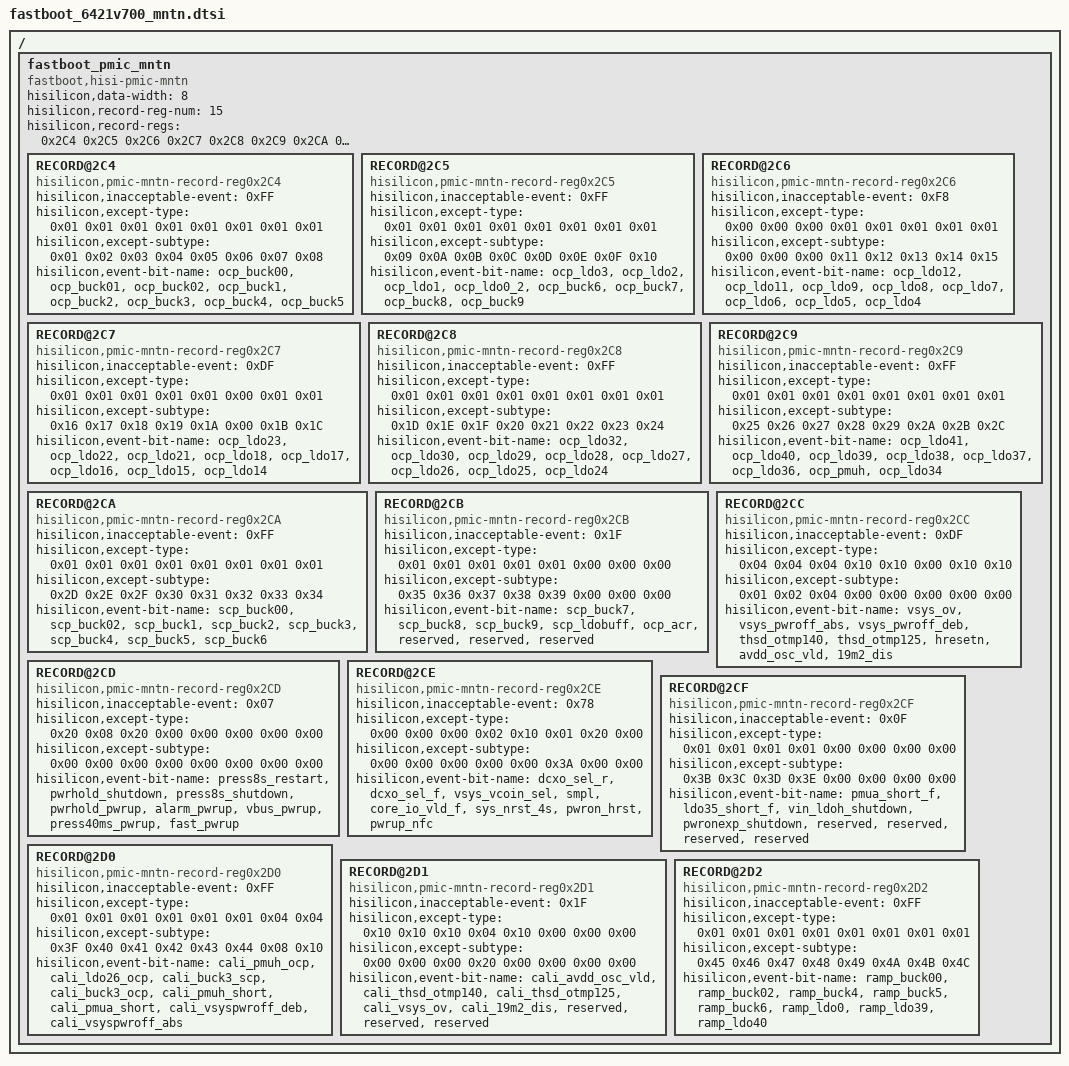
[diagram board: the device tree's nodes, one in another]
/******************************************************************************

                  版权所有 (C), 2001-2011, 华为技术有限公司

 ******************************************************************************

  This is an AUTO GENERATED file ! DON'T MODIFY MANUAL!
  文 件 名   : %(filename)s
  生成日期   : %(year)d年%(month)d月%(day)d日

******************************************************************************/

/ {
	fastboot_pmic_mntn: fastboot_pmic_mntn {
		compatible = "fastboot,hisi-pmic-mntn";
		hisilicon,data-width = <8>;
		hisilicon,record-reg-num = <15>;
		hisilicon,record-regs = <0x2C4 0x2C5 0x2C6 0x2C7 0x2C8 0x2C9 0x2CA 0x2CB 0x2CC 0x2CD 0x2CE 0x2CF 0x2D0 0x2D1 0x2D2>;

		RECORD@2C4 {
			compatible = "hisilicon,pmic-mntn-record-reg0x2C4";
			hisilicon,inacceptable-event = <0xFF>;
			/* every event must be signed a except type, and every except type is signed for a bit */
			/* 0x00:null; 0x01:except; 0x02:smpl; 0x04:scharger; 0x08:pwrhold; 0x10:pwroff_except; 0x20:pwroff_no_except */
			hisilicon,except-type = <0x01 0x01 0x01 0x01 0x01 0x01 0x01 0x01>;
			hisilicon,except-subtype = <0x01 0x02 0x03 0x04 0x05 0x06 0x07 0x08>;
			/* max len of per event-bit-name is 20 bytes */
			hisilicon,event-bit-name = "ocp_buck00","ocp_buck01","ocp_buck02","ocp_buck1","ocp_buck2","ocp_buck3","ocp_buck4","ocp_buck5";
		};

		RECORD@2C5 {
			compatible = "hisilicon,pmic-mntn-record-reg0x2C5";
			hisilicon,inacceptable-event = <0xFF>;
			hisilicon,except-type = <0x01 0x01 0x01 0x01 0x01 0x01 0x01 0x01>;
			hisilicon,except-subtype = <0x09 0x0A 0x0B 0x0C 0x0D 0x0E 0x0F 0x10>;
			hisilicon,event-bit-name = "ocp_ldo3","ocp_ldo2","ocp_ldo1","ocp_ldo0_2","ocp_buck6","ocp_buck7","ocp_buck8","ocp_buck9";
		};

		RECORD@2C6 {
			compatible = "hisilicon,pmic-mntn-record-reg0x2C6";
			hisilicon,inacceptable-event = <0xF8>;
			hisilicon,except-type = <0x00 0x00 0x00 0x01 0x01 0x01 0x01 0x01>;
			hisilicon,except-subtype = <0x00 0x00 0x00 0x11 0x12 0x13 0x14 0x15>;
			hisilicon,event-bit-name = "ocp_ldo12","ocp_ldo11","ocp_ldo9","ocp_ldo8","ocp_ldo7","ocp_ldo6","ocp_ldo5","ocp_ldo4";
		};

		RECORD@2C7 {
			compatible = "hisilicon,pmic-mntn-record-reg0x2C7";
			hisilicon,inacceptable-event = <0xDF>;
			hisilicon,except-type = <0x01 0x01 0x01 0x01 0x01 0x00 0x01 0x01>;
			hisilicon,except-subtype = <0x16 0x17 0x18 0x19 0x1A 0x00 0x1B 0x1C>;
			hisilicon,event-bit-name = "ocp_ldo23","ocp_ldo22","ocp_ldo21","ocp_ldo18","ocp_ldo17","ocp_ldo16","ocp_ldo15","ocp_ldo14";
		};

		RECORD@2C8 {
			compatible = "hisilicon,pmic-mntn-record-reg0x2C8";
			hisilicon,inacceptable-event = <0xFF>;
			hisilicon,except-type = <0x01 0x01 0x01 0x01 0x01 0x01 0x01 0x01>;
			hisilicon,except-subtype = <0x1D 0x1E 0x1F 0x20 0x21 0x22 0x23 0x24>;
			hisilicon,event-bit-name = "ocp_ldo32","ocp_ldo30","ocp_ldo29","ocp_ldo28","ocp_ldo27","ocp_ldo26","ocp_ldo25","ocp_ldo24";
		};

		RECORD@2C9 {
			compatible = "hisilicon,pmic-mntn-record-reg0x2C9";
			hisilicon,inacceptable-event = <0xFF>;
			hisilicon,except-type = <0x01 0x01 0x01 0x01 0x01 0x01 0x01 0x01>;
			hisilicon,except-subtype = <0x25 0x26 0x27 0x28 0x29 0x2A 0x2B 0x2C>;
			hisilicon,event-bit-name = "ocp_ldo41","ocp_ldo40","ocp_ldo39","ocp_ldo38","ocp_ldo37","ocp_ldo36","ocp_pmuh","ocp_ldo34";
		};

		RECORD@2CA {
			compatible = "hisilicon,pmic-mntn-record-reg0x2CA";
			hisilicon,inacceptable-event = <0xFF>;
			hisilicon,except-type = <0x01 0x01 0x01 0x01 0x01 0x01 0x01 0x01>;
			hisilicon,except-subtype = <0x2D 0x2E 0x2F 0x30 0x31 0x32 0x33 0x34>;
			hisilicon,event-bit-name = "scp_buck00","scp_buck02","scp_buck1","scp_buck2","scp_buck3","scp_buck4","scp_buck5","scp_buck6";
		};

		RECORD@2CB {
			compatible = "hisilicon,pmic-mntn-record-reg0x2CB";
			hisilicon,inacceptable-event = <0x1F>;
			hisilicon,except-type = <0x01 0x01 0x01 0x01 0x01 0x00 0x00 0x00>;
			hisilicon,except-subtype = <0x35 0x36 0x37 0x38 0x39 0x00 0x00 0x00>;
			hisilicon,event-bit-name = "scp_buck7","scp_buck8","scp_buck9","scp_ldobuff","ocp_acr","reserved","reserved","reserved";
		};

		RECORD@2CC {
			compatible = "hisilicon,pmic-mntn-record-reg0x2CC";
			hisilicon,inacceptable-event = <0xDF>;
			hisilicon,except-type = <0x04 0x04 0x04 0x10 0x10 0x00 0x10 0x10>;
			hisilicon,except-subtype = <0x01 0x02 0x04 0x00 0x00 0x00 0x00 0x00>;
			hisilicon,event-bit-name = "vsys_ov","vsys_pwroff_abs","vsys_pwroff_deb","thsd_otmp140","thsd_otmp125","hresetn","avdd_osc_vld","19m2_dis";
		};

		RECORD@2CD {
			compatible = "hisilicon,pmic-mntn-record-reg0x2CD";
			hisilicon,inacceptable-event = <0x07>;
			hisilicon,except-type = <0x20 0x08 0x20 0x00 0x00 0x00 0x00 0x00>;
			hisilicon,except-subtype = <0x00 0x00 0x00 0x00 0x00 0x00 0x00 0x00>;
			hisilicon,event-bit-name = "press8s_restart","pwrhold_shutdown","press8s_shutdown","pwrhold_pwrup","alarm_pwrup","vbus_pwrup","press40ms_pwrup","fast_pwrup";
		};

		RECORD@2CE {
			compatible = "hisilicon,pmic-mntn-record-reg0x2CE";
			hisilicon,inacceptable-event = <0x78>;
			hisilicon,except-type = <0x00 0x00 0x00 0x02 0x10 0x01 0x20 0x00>;
			hisilicon,except-subtype = <0x00 0x00 0x00 0x00 0x00 0x3A 0x00 0x00>;
			hisilicon,event-bit-name = "dcxo_sel_r","dcxo_sel_f","vsys_vcoin_sel","smpl","core_io_vld_f","sys_nrst_4s","pwron_hrst","pwrup_nfc";
		};

		RECORD@2CF {
			compatible = "hisilicon,pmic-mntn-record-reg0x2CF";
			hisilicon,inacceptable-event = <0x0F>;
			hisilicon,except-type = <0x01 0x01 0x01 0x01 0x00 0x00 0x00 0x00>;
			hisilicon,except-subtype = <0x3B 0x3C 0x3D 0x3E 0x00 0x00 0x00 0x00>;
			hisilicon,event-bit-name = "pmua_short_f","ldo35_short_f","vin_ldoh_shutdown","pwronexp_shutdown","reserved","reserved","reserved","reserved";
		};

		RECORD@2D0 {
			compatible = "hisilicon,pmic-mntn-record-reg0x2D0";
			hisilicon,inacceptable-event = <0xFF>;
			hisilicon,except-type = <0x01 0x01 0x01 0x01 0x01 0x01 0x04 0x04>;
			hisilicon,except-subtype = <0x3F 0x40 0x41 0x42 0x43 0x44 0x08 0x10>;
			hisilicon,event-bit-name = "cali_pmuh_ocp","cali_ldo26_ocp","cali_buck3_scp","cali_buck3_ocp","cali_pmuh_short","cali_pmua_short","cali_vsyspwroff_deb","cali_vsyspwroff_abs";
		};

		RECORD@2D1 {
			compatible = "hisilicon,pmic-mntn-record-reg0x2D1";
			hisilicon,inacceptable-event = <0x1F>;
			hisilicon,except-type = <0x10 0x10 0x10 0x04 0x10 0x00 0x00 0x00>;
			hisilicon,except-subtype = <0x00 0x00 0x00 0x20 0x00 0x00 0x00 0x00>;
			hisilicon,event-bit-name = "cali_avdd_osc_vld","cali_thsd_otmp140","cali_thsd_otmp125","cali_vsys_ov","cali_19m2_dis","reserved","reserved","reserved";
		};

		RECORD@2D2 {
			compatible = "hisilicon,pmic-mntn-record-reg0x2D2";
			hisilicon,inacceptable-event = <0xFF>;
			hisilicon,except-type = <0x01 0x01 0x01 0x01 0x01 0x01 0x01 0x01>;
			hisilicon,except-subtype = <0x45 0x46 0x47 0x48 0x49 0x4A 0x4B 0x4C>;
			hisilicon,event-bit-name = "ramp_buck00","ramp_buck02","ramp_buck4","ramp_buck5","ramp_buck6","ramp_ldo0","ramp_ldo39","ramp_ldo40";
		};
	};
};
